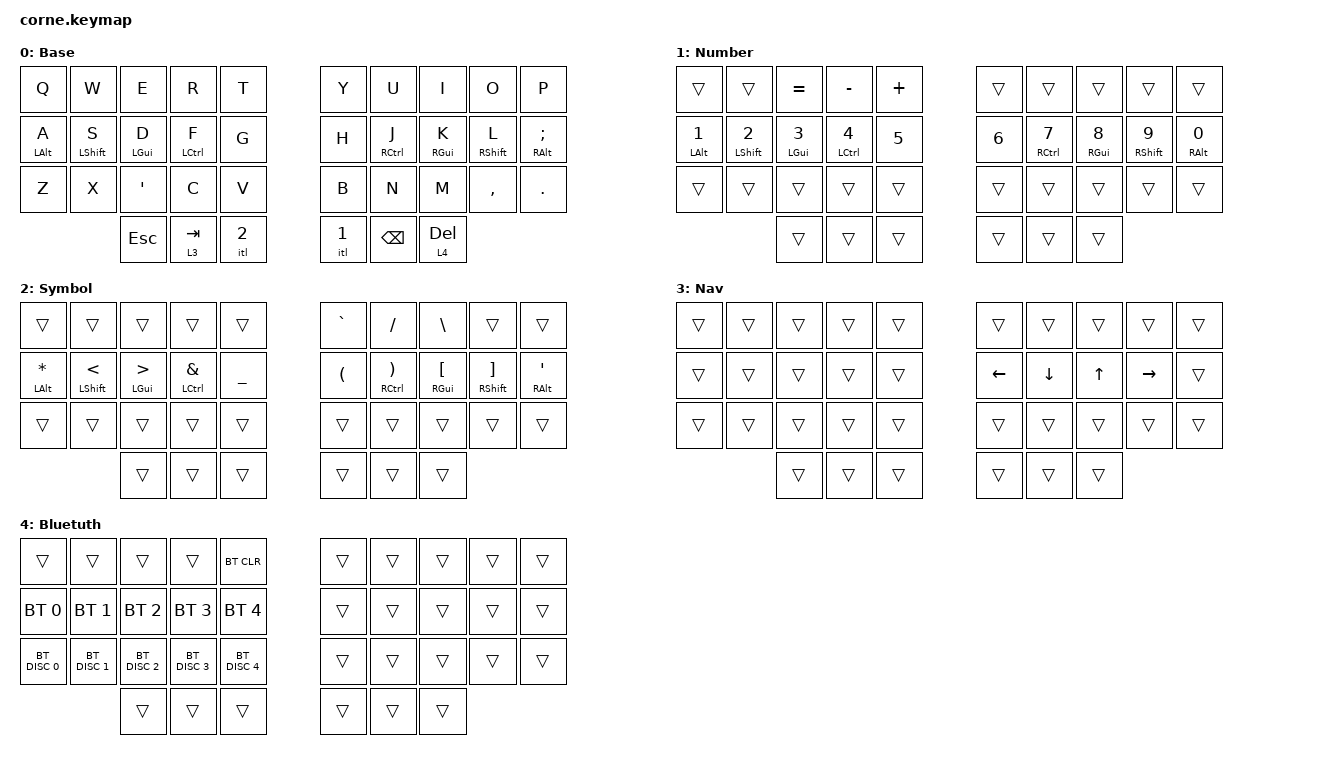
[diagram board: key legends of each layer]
/*
* Copyright (c) 2020 The ZMK Contributors
*
* SPDX-License-Identifier: MIT
*/

#include <behaviors.dtsi>
#include <dt-bindings/zmk/keys.h>
#include <dt-bindings/zmk/bt.h>

/ {
    chosen {
        zmk,physical-layout = &foostan_corne_5col_layout;
    };

    behaviors {
        hm: homerow_mods {
            compatible = "zmk,behavior-hold-tap";
            #binding-cells = <2>;
            bindings = <&kp>, <&kp>;

            flavor = "balanced";
            tapping-term-ms = <360>;
            require-prior-idle-ms = <180>;
            quick-tap-ms = <320>;
        };
        spcr: space_return {
            compatible = "zmk,behavior-mod-morph";
            #binding-cells = <0>;
            bindings = <&kp SPACE>, <&kp RET>;
            mods = <(MOD_LSFT|MOD_RSFT)>;
        };
        itl: inner_thumb_layers {
            compatible = "zmk,behavior-hold-tap";
            #binding-cells = <2>;
            bindings = <&mo>, <&spcr>;

            flavor = "balanced";
            tapping-term-ms = <420>;
            require-prior-idle-ms = <180>;
            quick-tap-ms = <380>;
        };
        otl: outer_thumb_layers {
            compatible = "zmk,behavior-hold-tap";
            #binding-cells = <2>;
            bindings = <&mo>, <&kp>;

            flavor = "balanced";
            tapping-term-ms = <420>;
            require-prior-idle-ms = <180>;
            quick-tap-ms = <380>;
        };
    };

    keymap {
        compatible = "zmk,keymap";
        base_layer {
            // qwerty with homerow mods
            display-name = "Base";
            bindings = <
                // ╭─────────────┬─────────────┬─────────────┬─────────────┬─────────────╮    ╭─────────────┬─────────────┬─────────────┬─────────────┬─────────────╮
                    &kp Q         &kp W         &kp E         &kp R         &kp T              &kp Y         &kp U         &kp I         &kp O         &kp P
                // ├─────────────┼─────────────┼─────────────┼─────────────┼─────────────┤    ├─────────────┼─────────────┼─────────────┼─────────────┼─────────────┤
                    &hm LALT A    &hm LSHFT S   &hm LGUI D    &hm LCTL F    &kp G              &kp H         &hm RCTL J    &hm RGUI K    &hm RSHFT L   &hm RALT SEMI
                // ├─────────────┼─────────────┼─────────────┼─────────────┼─────────────┤    ├─────────────┼─────────────┼─────────────┼─────────────┼─────────────┤
                    &kp Z         &kp X         &kp SQT       &kp C         &kp V              &kp B         &kp N         &kp M         &kp COMMA     &kp DOT
                // ╰─────────────┴─────────────┼─────────────┼─────────────┼─────────────┤    ├─────────────┼─────────────┼─────────────┼─────────────┴─────────────╯
                                                &kp ESC       &otl 3 TAB    &itl 2             &itl 1        &kp BSPC      &otl 4 DEL
                //                             ╰─────────────┴─────────────┴─────────────╯    ╰─────────────┴─────────────┴─────────────╯
            >;
        };
        number_layer {
            display-name = "Number";
            bindings = <
                // ╭─────────────┬─────────────┬─────────────┬─────────────┬─────────────╮    ╭─────────────┬─────────────┬─────────────┬─────────────┬─────────────╮
                    &trans        &trans        &kp EQUAL     &kp MINUS     &kp PLUS           &trans        &trans        &trans        &trans        &trans
                // ├─────────────┼─────────────┼─────────────┼─────────────┼─────────────┤    ├─────────────┼─────────────┼─────────────┼─────────────┼─────────────┤
                    &hm LALT N1   &hm LSHFT N2  &hm LGUI N3   &hm LCTL N4   &kp N5             &kp N6        &hm RCTL N7   &hm RGUI N8   &hm RSHFT N9  &hm RALT N0
                // ├─────────────┼─────────────┼─────────────┼─────────────┼─────────────┤    ├─────────────┼─────────────┼─────────────┼─────────────┼─────────────┤
                    &trans        &trans        &trans        &trans        &trans             &trans        &trans        &trans        &trans        &trans
                // ╰─────────────┴─────────────┼─────────────┼─────────────┼─────────────┤    ├─────────────┼─────────────┼─────────────┼─────────────┴─────────────╯
                                                &trans        &trans        &trans             &trans        &trans        &trans
                //                             ╰─────────────┴─────────────┴─────────────╯    ╰─────────────┴─────────────┴─────────────╯
            >;
        };
        symbol_layer {
            display-name = "Symbol";
            bindings = <
                // ╭─────────────┬─────────────┬─────────────┬─────────────┬─────────────╮    ╭─────────────┬─────────────┬─────────────┬─────────────┬─────────────╮
                    &trans        &trans        &trans        &trans        &trans             &kp GRAVE     &kp FSLH      &kp BSLH      &trans        &trans
                // ├─────────────┼─────────────┼─────────────┼─────────────┼─────────────┤    ├─────────────┼─────────────┼─────────────┼─────────────┼─────────────┤
                    &hm LALT STAR &hm LSHFT LT  &hm LGUI GT   &hm LCTL AMPS &kp UNDER          &kp LPAR      &hm RCTL RPAR &hm RGUI LBKT &hm RSHFT RBKT&hm RALT SQT
                // ├─────────────┼─────────────┼─────────────┼─────────────┼─────────────┤    ├─────────────┼─────────────┼─────────────┼─────────────┼─────────────┤
                    &trans        &trans        &trans        &trans        &trans             &trans        &trans        &trans        &trans        &trans
                // ╰─────────────┴─────────────┼─────────────┼─────────────┼─────────────┤    ├─────────────┼─────────────┼─────────────┼─────────────┴─────────────╯
                                                &trans        &trans        &trans             &trans        &trans        &trans
                //                             ╰─────────────┴─────────────┴─────────────╯    ╰─────────────┴─────────────┴─────────────╯
            >;
        };
        nav_layer {
            display-name = "Nav";
            bindings = <
                // ╭─────────────┬─────────────┬─────────────┬─────────────┬─────────────╮    ╭─────────────┬─────────────┬─────────────┬─────────────┬─────────────╮
                    &trans        &trans        &trans        &trans        &trans             &trans        &trans        &trans        &trans        &trans
                // ├─────────────┼─────────────┼─────────────┼─────────────┼─────────────┤    ├─────────────┼─────────────┼─────────────┼─────────────┼─────────────┤
                    &trans        &trans        &trans        &trans        &trans             &kp LEFT      &kp DOWN      &kp UP        &kp RIGHT     &trans
                // ├─────────────┼─────────────┼─────────────┼─────────────┼─────────────┤    ├─────────────┼─────────────┼─────────────┼─────────────┼─────────────┤
                    &trans        &trans        &trans        &trans        &trans             &trans        &trans        &trans        &trans        &trans
                // ╰─────────────┴─────────────┼─────────────┼─────────────┼─────────────┤    ├─────────────┼─────────────┼─────────────┼─────────────┴─────────────╯
                                                &trans        &trans        &trans             &trans        &trans        &trans
                //                             ╰─────────────┴─────────────┴─────────────╯    ╰─────────────┴─────────────┴─────────────╯
            >;
        };
        bt_layer {
            display-name = "Bluetuth";
            bindings = <
                // ╭─────────────┬─────────────┬─────────────┬─────────────┬─────────────╮    ╭─────────────┬─────────────┬─────────────┬─────────────┬─────────────╮
                    &trans        &trans        &trans        &trans        &bt BT_CLR         &trans        &trans        &trans        &trans        &trans
                // ├─────────────┼─────────────┼─────────────┼─────────────┼─────────────┤    ├─────────────┼─────────────┼─────────────┼─────────────┼─────────────┤
                    &bt BT_SEL 0  &bt BT_SEL 1  &bt BT_SEL 2  &bt BT_SEL 3  &bt BT_SEL 4       &trans        &trans        &trans        &trans        &trans        
                // ├─────────────┼─────────────┼─────────────┼─────────────┼─────────────┤    ├─────────────┼─────────────┼─────────────┼─────────────┼─────────────┤
                    &bt BT_DISC 0 &bt BT_DISC 1 &bt BT_DISC 2 &bt BT_DISC 3 &bt BT_DISC 4      &trans        &trans        &trans        &trans        &trans
                // ╰─────────────┴─────────────┼─────────────┼─────────────┼─────────────┤    ├─────────────┼─────────────┼─────────────┼─────────────┴─────────────╯
                                                &trans        &trans        &trans             &trans        &trans        &trans
                //                             ╰─────────────┴─────────────┴─────────────╯    ╰─────────────┴─────────────┴─────────────╯
            >;
        };

    }; 

    combos {
        compatible = "zmk,combos";
        combo_esc {
            timeout-ms = <60>;
            key-positions = <32 33>;
            bindings = <&kp ESC>;
        };
        combo_caps {
            timeout-ms = <30>;
            key-positions = <11 18>;
            bindings = <&kp CAPS>;
        };
    };
};
